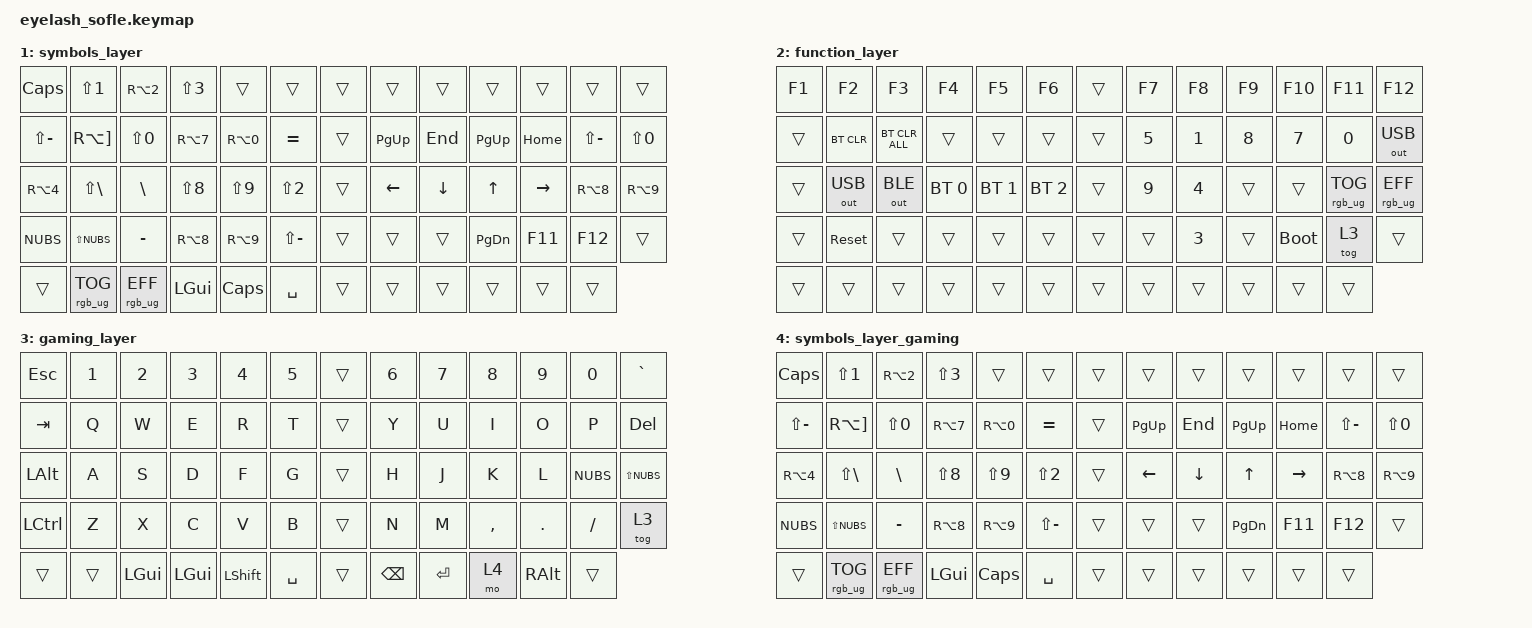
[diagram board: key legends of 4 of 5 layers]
#include <behaviors.dtsi>
#include <dt-bindings/zmk/bt.h>
#include <dt-bindings/zmk/keys.h>
#include <dt-bindings/zmk/outputs.h>
#include <dt-bindings/zmk/rgb.h>
//comment
/ {
    behaviors {

        mt_h: mod_tap {
            compatible = "zmk,behavior-hold-tap";
            tapping-term-ms = <100>;
            flavor = "tap-preferred";
            bindings = <&kp>, <&kp>;
            display-name = "Mod-Tap";
        };
        hml: home_row_mod_left {
            compatible = "zmk,behavior-hold-tap";
            #binding-cells = <2>;
            flavor = "balanced";
            require-prior-idle-ms = <150>;
            tapping-term-ms = <280>;
            quick-tap-ms = <175>;
            bindings = <&kp>, <&kp>;
            hold-trigger-key-positions = <6 7 8 9 10 11 18 19 20 21 22 23 30 31 32 33 34 35 42 43 44 45 46 47 54 55 56 57>;
            hold-trigger-on-release;
        };
        hmr: home_row_mod_right {
            compatible = "zmk,behavior-hold-tap";
            #binding-cells = <2>;
            flavor = "balanced";
            require-prior-idle-ms = <150>;
            tapping-term-ms = <280>;
            quick-tap-ms = <175>;
            bindings = <&kp>, <&kp>;
            hold-trigger-key-positions = <0 1 2 3 4 5 12 13 14 15 16 17 24 25 26 27 28 29 36 37 38 39 40 41 48 49 50 51 52 53>;
            hold-trigger-on-release;
        };
};
    keymap {
        compatible = "zmk,keymap";

        // Layer 0 - Base layer with home row mods

        default_layer {
            bindings = <
&kp GRAVE  &kp N1     &kp N2        &kp N3        &kp N4        &kp N5       &kp UP_ARROW     &kp N6    &kp N7        &kp N8        &kp N9    &kp N0           &kp MINUS
&kp TAB    &kp Q      &kp W         &kp E         &kp R         &kp T        &kp DOWN_ARROW   &kp Y     &kp U         &kp I         &kp O     &kp P            &kp LBKT
&mo 2      &kp A      &kp S         &hml LCTRL D  &hml LSHFT F  &kp G        &kp LEFT_ARROW   &kp H     &hmr RSHFT J  &hmr RCTRL K  &kp L     &kp 1 SEMI       &kp SQT
&kp ESC    &kp Z      &kp X         &kp C         &kp V         &kp B        &kp RIGHT_ARROW  &kp N     &kp M         &kp COMMA     &kp DOT   &kp FSLH         &kp DEL
&trans     &kp LCTRL  &kp LEFT_ALT  &kp LGUI      &kp LEFT_ALT  &kp SPACE    &kp ENTER        &kp BSPC  &kp ENTER     &mo 1         &kp RALT  &tog 3
            >;
        };

        // Layer 1 - Symbols (Norwegian layout compatible)

        symbols_layer {
            bindings = <
&kp CAPS       &kp LS(N1)       &kp RA(N2)       &kp LS(N3)  &trans      &trans           &trans  &trans          &trans    &trans         &trans     &trans         &trans
&kp LS(MINUS)  &kp RA(RBKT)     &kp LS(N0)       &kp RA(N7)  &kp RA(N0)  &kp EQUAL        &trans  &kp PG_UP       &kp END   &kp PAGE_UP    &kp HOME   &kp LS(MINUS)  &kp LS(N0)
&kp RA(N4)     &kp LS(BSLH)     &kp BSLH         &kp LS(N8)  &kp LS(N9)  &kp LS(N2)       &trans  &kp LEFT_ARROW  &kp DOWN  &kp UP_ARROW   &kp RIGHT  &kp RA(N8)     &kp RA(N9)
&kp NUBS       &kp LS(NUBS)     &kp MINUS        &kp RA(N8)  &kp RA(N9)  &kp LS(MINUS)    &trans  &trans          &trans    &kp PAGE_DOWN  &kp F11    &kp F12        &trans
&trans         &rgb_ug RGB_TOG  &rgb_ug RGB_EFF  &kp LGUI    &kp CAPS    &kp SPACE        &trans  &trans          &trans    &trans         &trans     &trans
            >;
        };

        // Layer 2 - Function keys and system

        function_layer {
            bindings = <
&kp F1  &kp F2        &kp F3          &kp F4        &kp F5        &kp F6          &trans  &kp F7  &kp F8  &kp F9  &kp F10      &kp F11          &kp F12
&trans  &bt BT_CLR    &bt BT_CLR_ALL  &trans        &trans        &trans          &trans  &kp N5  &kp N1  &kp N8  &kp N7       &kp N0           &out OUT_USB
&trans  &out OUT_USB  &out OUT_BLE    &bt BT_SEL 0  &bt BT_SEL 1  &bt BT_SEL 2    &trans  &kp N9  &kp N4  &trans  &trans       &rgb_ug RGB_TOG  &rgb_ug RGB_EFF
&trans  &sys_reset    &trans          &trans        &trans        &trans          &trans  &trans  &kp N3  &trans  &bootloader  &tog 3           &trans
&trans  &trans        &trans          &trans        &trans        &trans          &trans  &trans  &trans  &trans  &trans       &trans
            >;
        };

        // Layer 3 - Gaming layer (no home row mods)

        gaming_layer {
            bindings = <
&kp ESC    &kp N1  &kp N2    &kp N3    &kp N4          &kp N5       &trans  &kp N6         &kp N7     &kp N8     &kp N9    &kp N0    &kp GRAVE
&kp TAB    &kp Q   &kp W     &kp E     &kp R           &kp T        &trans  &kp Y          &kp U      &kp I      &kp O     &kp P     &kp DEL
&kp LALT   &kp A   &kp S     &kp D     &kp F           &kp G        &trans  &kp H          &kp J      &kp K      &kp L     &kp NUBS  &kp LS(NUBS)
&kp LCTRL  &kp Z   &kp X     &kp C     &kp V           &kp B        &trans  &kp N          &kp M      &kp COMMA  &kp DOT   &kp FSLH  &tog 3
&trans     &trans  &kp LGUI  &kp LGUI  &kp LEFT_SHIFT  &kp SPACE    &trans  &kp BACKSPACE  &kp ENTER  &mo 4      &kp RALT  &trans
            >;
        };

        // Layer 4, symbols for gaming toggle

        symbols_layer_gaming {
            bindings = <
&kp CAPS       &kp LS(N1)       &kp RA(N2)       &kp LS(N3)  &trans      &trans           &trans  &trans          &trans    &trans         &trans     &trans         &trans
&kp LS(MINUS)  &kp RA(RBKT)     &kp LS(N0)       &kp RA(N7)  &kp RA(N0)  &kp EQUAL        &trans  &kp PG_UP       &kp END   &kp PAGE_UP    &kp HOME   &kp LS(MINUS)  &kp LS(N0)
&kp RA(N4)     &kp LS(BSLH)     &kp BSLH         &kp LS(N8)  &kp LS(N9)  &kp LS(N2)       &trans  &kp LEFT_ARROW  &kp DOWN  &kp UP_ARROW   &kp RIGHT  &kp RA(N8)     &kp RA(N9)
&kp NUBS       &kp LS(NUBS)     &kp MINUS        &kp RA(N8)  &kp RA(N9)  &kp LS(MINUS)    &trans  &trans          &trans    &kp PAGE_DOWN  &kp F11    &kp F12        &trans
&trans         &rgb_ug RGB_TOG  &rgb_ug RGB_EFF  &kp LGUI    &kp CAPS    &kp SPACE        &trans  &trans          &trans    &trans         &trans     &trans
            >;
        };
    };
};
